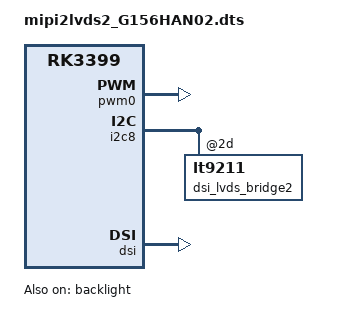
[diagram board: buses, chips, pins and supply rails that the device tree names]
/dts-v1/;
/plugin/;
/ {
	compatible = "rockchip,rk3399";

	fragment@0 {
		target = <&pwm0>;
		__overlay__ {
			status = "okay";
		};
	};
	fragment@1 {
		target = <&backlight>;
		__overlay__ {
			status = "okay";
            pwms = <&pwm0 0 5000000 0>;
			power-sequence-reverse;
            enable_delay = <10>;
            disable_delay = <0>;
            minimal-brightness-level = <30>;
		};
	};
	fragment@2 {
		target = <&i2c8>;
		__overlay__ {
			status = "okay";
			dsi_lvds_bridge2: lt9211@2d {
				status = "okay";
				dsi-lanes = <4>;
				lvds-format = <2>;//VESA
				lvds-bpp = <24>;
				de-mode;
				dual-link;
				enable-overlay;
				//test-pattern;
			};
		};
	};
	fragment@3 {
		target = <&dsi>;
		__overlay__ {
			status = "okay";
			panel@0 {
				backlight = <&backlight>;

				width-mm = <364>;
				height-mm = <216>;
				bpc=<8>;
				bus-format = <0x100a>;//<MEDIA_BUS_FMT_RGB888_1X24>;
				dsi,flags = <0x03>;
				dsi,format = <0>;//MIPI_DSI_FMT_RGB888:
				dsi,lanes = <4>;

				t1=<40>;//VCC on to start lvds signal
				t2=<250>;//t2-t6: LVDS signal(start) to turn Backlihgt on or Backlight sys Enable
				t3=<150>;//Backlight sys Disable or Backlihgt(off) to stop lvds signal
				t4=<20>;//LVDS signal to turn VCC off
				t5=<1000>;//VCC off to turn VCC on
				t6=<10>;//Backlight sys Enable to turn Backlight on
				t7=<10>;//Backlight off to Backlight sys Disable
				//t1 -> t2-t6 -> t6 -> t3 -> t7 -> t4 -> t5

				display-timings {
					native-mode = <&timing84>;//keep use for 84 timing

					timing84: timing84  {
                        clock-frequency = <141000000>;
                        hactive = <1920>;
                        vactive = <1080>;
                        hfront-porch = <72>;
                        hback-porch = <72>;
                        hsync-len = <40>;
                        vfront-porch = <15>;
                        vsync-len = <6>;
                        vback-porch = <15>;
                        hsync-active = <0>;
                        vsync-active = <0>;
                        de-active = <1>;
                       	pixelclk-active = <0>;
					};
				};
			};
		};
	};
	fragment@4 {
		target = <&pinctrl>;
		__overlay__ {
			pinctrl-0 = <&gpio_init2>;
			gpio_init_config {
				gpio_init2: gpio_init2 {
					rockchip,pins =
						<2 19 0 &pcfg_pull_none>;
				};
			};
		};
	};
};
